VERSION ""

NS_ :

BS_:

BU_:

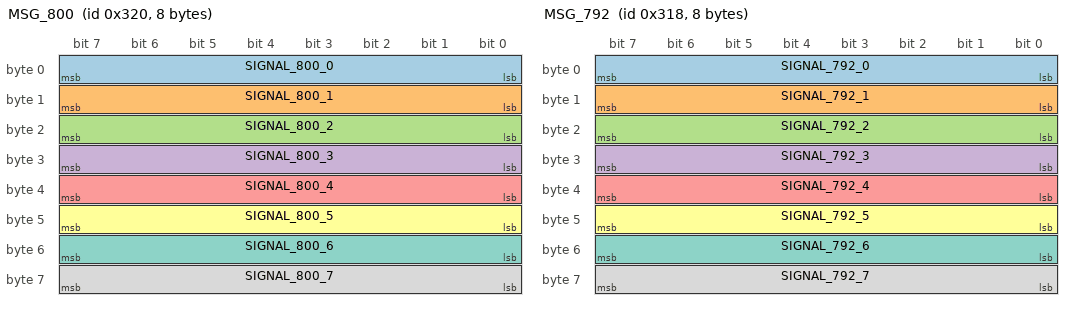
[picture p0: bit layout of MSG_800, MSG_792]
BO_ 800 MSG_800 : 8 VECTOR
    SG_ SIGNAL_800_0 : 0|8@1+ (1,0) [0|255] "" VECTOR
    SG_ SIGNAL_800_1 : 8|8@1+ (1,0) [0|255] "" VECTOR
    SG_ SIGNAL_800_2 : 16|8@1+ (1,0) [0|255] "" VECTOR
    SG_ SIGNAL_800_3 : 24|8@1+ (1,0) [0|255] "" VECTOR
    SG_ SIGNAL_800_4 : 32|8@1+ (1,0) [0|255] "" VECTOR
    SG_ SIGNAL_800_5 : 40|8@1+ (1,0) [0|255] "" VECTOR
    SG_ SIGNAL_800_6 : 48|8@1+ (1,0) [0|255] "" VECTOR
    SG_ SIGNAL_800_7 : 56|8@1+ (1,0) [0|255] "" VECTOR

BO_ 792 MSG_792 : 8 VECTOR
    SG_ SIGNAL_792_0 : 0|8@1+ (1,0) [0|255] "" VECTOR
    SG_ SIGNAL_792_1 : 8|8@1+ (1,0) [0|255] "" VECTOR
    SG_ SIGNAL_792_2 : 16|8@1+ (1,0) [0|255] "" VECTOR
    SG_ SIGNAL_792_3 : 24|8@1+ (1,0) [0|255] "" VECTOR
    SG_ SIGNAL_792_4 : 32|8@1+ (1,0) [0|255] "" VECTOR
    SG_ SIGNAL_792_5 : 40|8@1+ (1,0) [0|255] "" VECTOR
    SG_ SIGNAL_792_6 : 48|8@1+ (1,0) [0|255] "" VECTOR
    SG_ SIGNAL_792_7 : 56|8@1+ (1,0) [0|255] "" VECTOR

BO_ 287 MSG_287 : 5 VECTOR
    SG_ SIGNAL_287_0 : 0|8@1+ (1,0) [0|255] "" VECTOR
    SG_ SIGNAL_287_1 : 8|8@1+ (1,0) [0|255] "" VECTOR
    SG_ SIGNAL_287_2 : 16|8@1+ (1,0) [0|255] "" VECTOR
    SG_ SIGNAL_287_3 : 24|8@1+ (1,0) [0|255] "" VECTOR
    SG_ SIGNAL_287_4 : 32|8@1+ (1,0) [0|255] "" VECTOR

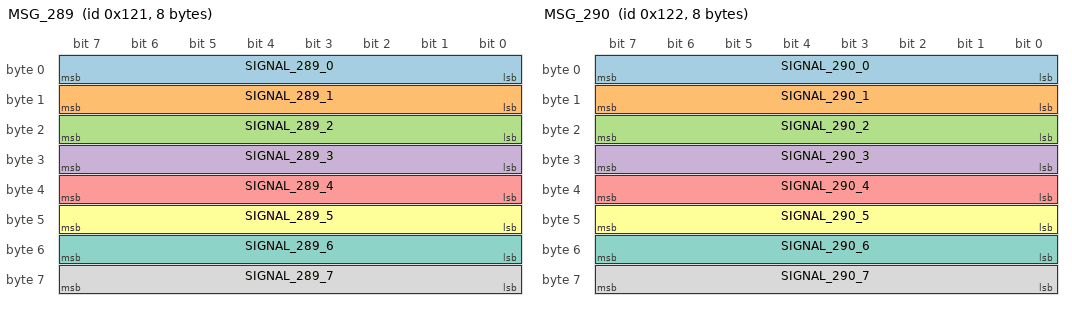
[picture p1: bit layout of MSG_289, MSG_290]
BO_ 289 MSG_289 : 8 VECTOR
    SG_ SIGNAL_289_0 : 0|8@1+ (1,0) [0|255] "" VECTOR
    SG_ SIGNAL_289_1 : 8|8@1+ (1,0) [0|255] "" VECTOR
    SG_ SIGNAL_289_2 : 16|8@1+ (1,0) [0|255] "" VECTOR
    SG_ SIGNAL_289_3 : 24|8@1+ (1,0) [0|255] "" VECTOR
    SG_ SIGNAL_289_4 : 32|8@1+ (1,0) [0|255] "" VECTOR
    SG_ SIGNAL_289_5 : 40|8@1+ (1,0) [0|255] "" VECTOR
    SG_ SIGNAL_289_6 : 48|8@1+ (1,0) [0|255] "" VECTOR
    SG_ SIGNAL_289_7 : 56|8@1+ (1,0) [0|255] "" VECTOR

BO_ 290 MSG_290 : 8 VECTOR
    SG_ SIGNAL_290_0 : 0|8@1+ (1,0) [0|255] "" VECTOR
    SG_ SIGNAL_290_1 : 8|8@1+ (1,0) [0|255] "" VECTOR
    SG_ SIGNAL_290_2 : 16|8@1+ (1,0) [0|255] "" VECTOR
    SG_ SIGNAL_290_3 : 24|8@1+ (1,0) [0|255] "" VECTOR
    SG_ SIGNAL_290_4 : 32|8@1+ (1,0) [0|255] "" VECTOR
    SG_ SIGNAL_290_5 : 40|8@1+ (1,0) [0|255] "" VECTOR
    SG_ SIGNAL_290_6 : 48|8@1+ (1,0) [0|255] "" VECTOR
    SG_ SIGNAL_290_7 : 56|8@1+ (1,0) [0|255] "" VECTOR

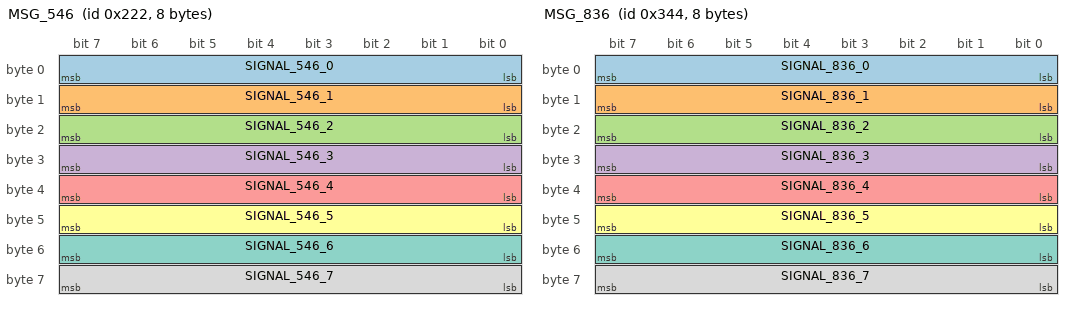
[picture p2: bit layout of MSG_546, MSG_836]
BO_ 546 MSG_546 : 8 VECTOR
    SG_ SIGNAL_546_0 : 0|8@1+ (1,0) [0|255] "" VECTOR
    SG_ SIGNAL_546_1 : 8|8@1+ (1,0) [0|255] "" VECTOR
    SG_ SIGNAL_546_2 : 16|8@1+ (1,0) [0|255] "" VECTOR
    SG_ SIGNAL_546_3 : 24|8@1+ (1,0) [0|255] "" VECTOR
    SG_ SIGNAL_546_4 : 32|8@1+ (1,0) [0|255] "" VECTOR
    SG_ SIGNAL_546_5 : 40|8@1+ (1,0) [0|255] "" VECTOR
    SG_ SIGNAL_546_6 : 48|8@1+ (1,0) [0|255] "" VECTOR
    SG_ SIGNAL_546_7 : 56|8@1+ (1,0) [0|255] "" VECTOR

BO_ 836 MSG_836 : 8 VECTOR
    SG_ SIGNAL_836_0 : 0|8@1+ (1,0) [0|255] "" VECTOR
    SG_ SIGNAL_836_1 : 8|8@1+ (1,0) [0|255] "" VECTOR
    SG_ SIGNAL_836_2 : 16|8@1+ (1,0) [0|255] "" VECTOR
    SG_ SIGNAL_836_3 : 24|8@1+ (1,0) [0|255] "" VECTOR
    SG_ SIGNAL_836_4 : 32|8@1+ (1,0) [0|255] "" VECTOR
    SG_ SIGNAL_836_5 : 40|8@1+ (1,0) [0|255] "" VECTOR
    SG_ SIGNAL_836_6 : 48|8@1+ (1,0) [0|255] "" VECTOR
    SG_ SIGNAL_836_7 : 56|8@1+ (1,0) [0|255] "" VECTOR

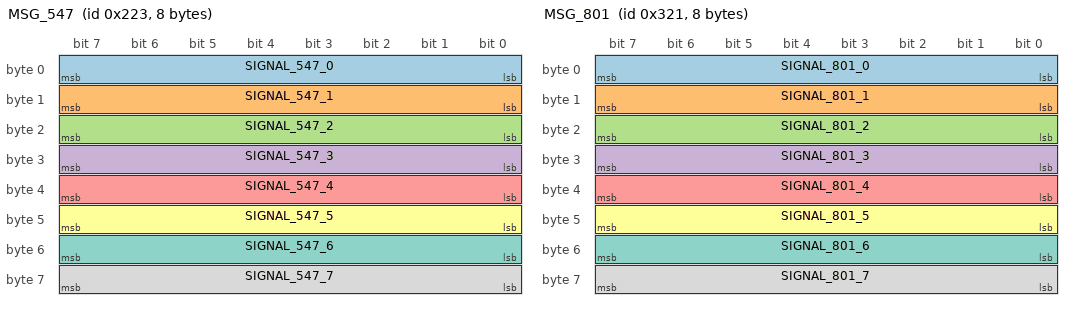
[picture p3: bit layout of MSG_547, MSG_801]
BO_ 547 MSG_547 : 8 VECTOR
    SG_ SIGNAL_547_0 : 0|8@1+ (1,0) [0|255] "" VECTOR
    SG_ SIGNAL_547_1 : 8|8@1+ (1,0) [0|255] "" VECTOR
    SG_ SIGNAL_547_2 : 16|8@1+ (1,0) [0|255] "" VECTOR
    SG_ SIGNAL_547_3 : 24|8@1+ (1,0) [0|255] "" VECTOR
    SG_ SIGNAL_547_4 : 32|8@1+ (1,0) [0|255] "" VECTOR
    SG_ SIGNAL_547_5 : 40|8@1+ (1,0) [0|255] "" VECTOR
    SG_ SIGNAL_547_6 : 48|8@1+ (1,0) [0|255] "" VECTOR
    SG_ SIGNAL_547_7 : 56|8@1+ (1,0) [0|255] "" VECTOR

BO_ 801 MSG_801 : 8 VECTOR
    SG_ SIGNAL_801_0 : 0|8@1+ (1,0) [0|255] "" VECTOR
    SG_ SIGNAL_801_1 : 8|8@1+ (1,0) [0|255] "" VECTOR
    SG_ SIGNAL_801_2 : 16|8@1+ (1,0) [0|255] "" VECTOR
    SG_ SIGNAL_801_3 : 24|8@1+ (1,0) [0|255] "" VECTOR
    SG_ SIGNAL_801_4 : 32|8@1+ (1,0) [0|255] "" VECTOR
    SG_ SIGNAL_801_5 : 40|8@1+ (1,0) [0|255] "" VECTOR
    SG_ SIGNAL_801_6 : 48|8@1+ (1,0) [0|255] "" VECTOR
    SG_ SIGNAL_801_7 : 56|8@1+ (1,0) [0|255] "" VECTOR

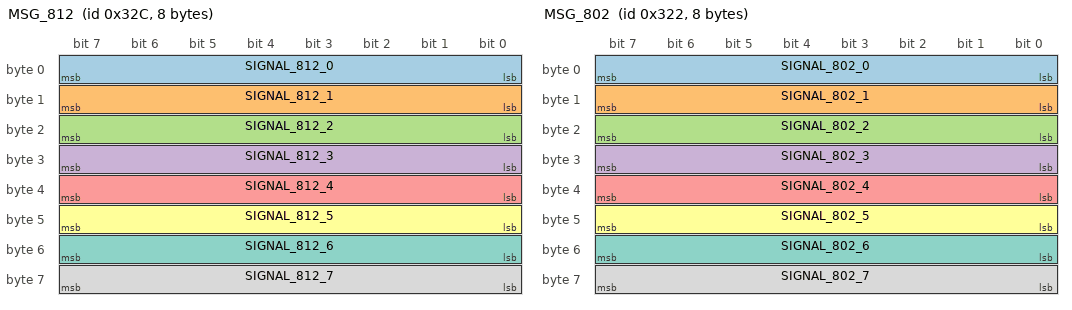
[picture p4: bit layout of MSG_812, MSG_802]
BO_ 812 MSG_812 : 8 VECTOR
    SG_ SIGNAL_812_0 : 0|8@1+ (1,0) [0|255] "" VECTOR
    SG_ SIGNAL_812_1 : 8|8@1+ (1,0) [0|255] "" VECTOR
    SG_ SIGNAL_812_2 : 16|8@1+ (1,0) [0|255] "" VECTOR
    SG_ SIGNAL_812_3 : 24|8@1+ (1,0) [0|255] "" VECTOR
    SG_ SIGNAL_812_4 : 32|8@1+ (1,0) [0|255] "" VECTOR
    SG_ SIGNAL_812_5 : 40|8@1+ (1,0) [0|255] "" VECTOR
    SG_ SIGNAL_812_6 : 48|8@1+ (1,0) [0|255] "" VECTOR
    SG_ SIGNAL_812_7 : 56|8@1+ (1,0) [0|255] "" VECTOR

BO_ 802 MSG_802 : 8 VECTOR
    SG_ SIGNAL_802_0 : 0|8@1+ (1,0) [0|255] "" VECTOR
    SG_ SIGNAL_802_1 : 8|8@1+ (1,0) [0|255] "" VECTOR
    SG_ SIGNAL_802_2 : 16|8@1+ (1,0) [0|255] "" VECTOR
    SG_ SIGNAL_802_3 : 24|8@1+ (1,0) [0|255] "" VECTOR
    SG_ SIGNAL_802_4 : 32|8@1+ (1,0) [0|255] "" VECTOR
    SG_ SIGNAL_802_5 : 40|8@1+ (1,0) [0|255] "" VECTOR
    SG_ SIGNAL_802_6 : 48|8@1+ (1,0) [0|255] "" VECTOR
    SG_ SIGNAL_802_7 : 56|8@1+ (1,0) [0|255] "" VECTOR

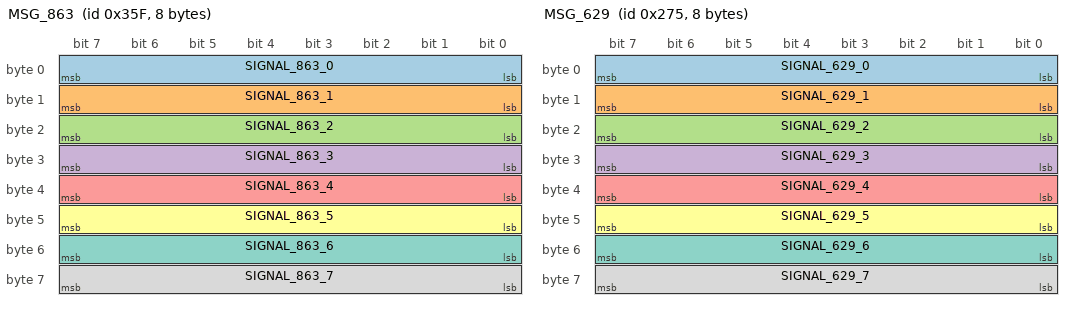
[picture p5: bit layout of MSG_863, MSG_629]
BO_ 863 MSG_863 : 8 VECTOR
    SG_ SIGNAL_863_0 : 0|8@1+ (1,0) [0|255] "" VECTOR
    SG_ SIGNAL_863_1 : 8|8@1+ (1,0) [0|255] "" VECTOR
    SG_ SIGNAL_863_2 : 16|8@1+ (1,0) [0|255] "" VECTOR
    SG_ SIGNAL_863_3 : 24|8@1+ (1,0) [0|255] "" VECTOR
    SG_ SIGNAL_863_4 : 32|8@1+ (1,0) [0|255] "" VECTOR
    SG_ SIGNAL_863_5 : 40|8@1+ (1,0) [0|255] "" VECTOR
    SG_ SIGNAL_863_6 : 48|8@1+ (1,0) [0|255] "" VECTOR
    SG_ SIGNAL_863_7 : 56|8@1+ (1,0) [0|255] "" VECTOR

BO_ 629 MSG_629 : 8 VECTOR
    SG_ SIGNAL_629_0 : 0|8@1+ (1,0) [0|255] "" VECTOR
    SG_ SIGNAL_629_1 : 8|8@1+ (1,0) [0|255] "" VECTOR
    SG_ SIGNAL_629_2 : 16|8@1+ (1,0) [0|255] "" VECTOR
    SG_ SIGNAL_629_3 : 24|8@1+ (1,0) [0|255] "" VECTOR
    SG_ SIGNAL_629_4 : 32|8@1+ (1,0) [0|255] "" VECTOR
    SG_ SIGNAL_629_5 : 40|8@1+ (1,0) [0|255] "" VECTOR
    SG_ SIGNAL_629_6 : 48|8@1+ (1,0) [0|255] "" VECTOR
    SG_ SIGNAL_629_7 : 56|8@1+ (1,0) [0|255] "" VECTOR

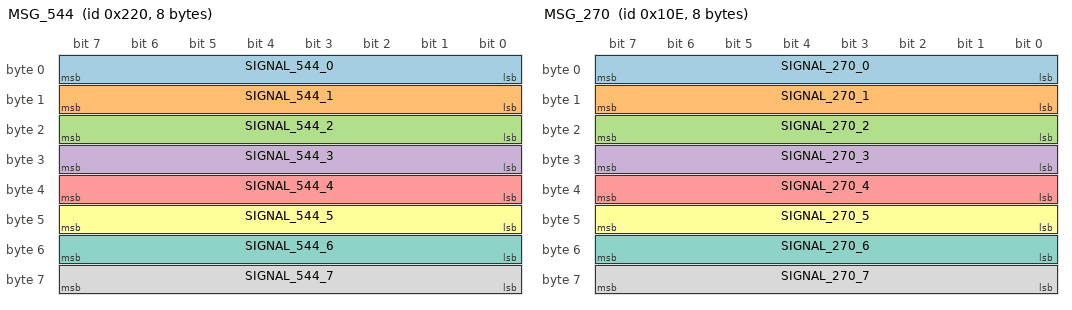
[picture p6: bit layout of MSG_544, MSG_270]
BO_ 544 MSG_544 : 8 VECTOR
    SG_ SIGNAL_544_0 : 0|8@1+ (1,0) [0|255] "" VECTOR
    SG_ SIGNAL_544_1 : 8|8@1+ (1,0) [0|255] "" VECTOR
    SG_ SIGNAL_544_2 : 16|8@1+ (1,0) [0|255] "" VECTOR
    SG_ SIGNAL_544_3 : 24|8@1+ (1,0) [0|255] "" VECTOR
    SG_ SIGNAL_544_4 : 32|8@1+ (1,0) [0|255] "" VECTOR
    SG_ SIGNAL_544_5 : 40|8@1+ (1,0) [0|255] "" VECTOR
    SG_ SIGNAL_544_6 : 48|8@1+ (1,0) [0|255] "" VECTOR
    SG_ SIGNAL_544_7 : 56|8@1+ (1,0) [0|255] "" VECTOR

BO_ 270 MSG_270 : 8 VECTOR
    SG_ SIGNAL_270_0 : 0|8@1+ (1,0) [0|255] "" VECTOR
    SG_ SIGNAL_270_1 : 8|8@1+ (1,0) [0|255] "" VECTOR
    SG_ SIGNAL_270_2 : 16|8@1+ (1,0) [0|255] "" VECTOR
    SG_ SIGNAL_270_3 : 24|8@1+ (1,0) [0|255] "" VECTOR
    SG_ SIGNAL_270_4 : 32|8@1+ (1,0) [0|255] "" VECTOR
    SG_ SIGNAL_270_5 : 40|8@1+ (1,0) [0|255] "" VECTOR
    SG_ SIGNAL_270_6 : 48|8@1+ (1,0) [0|255] "" VECTOR
    SG_ SIGNAL_270_7 : 56|8@1+ (1,0) [0|255] "" VECTOR

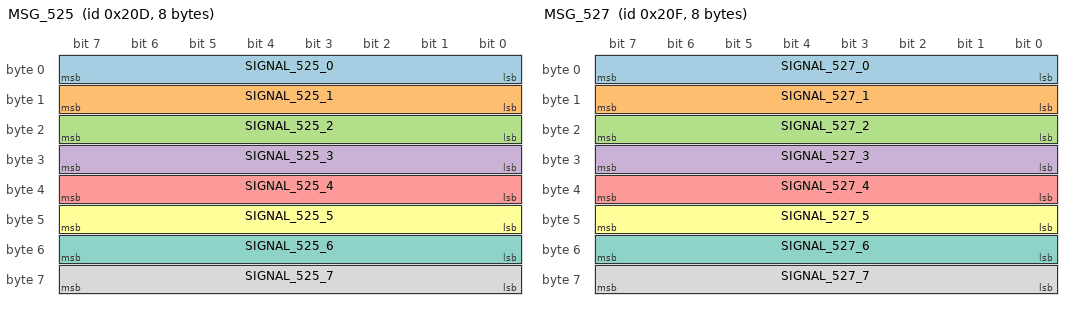
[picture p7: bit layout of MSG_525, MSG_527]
BO_ 525 MSG_525 : 8 VECTOR
    SG_ SIGNAL_525_0 : 0|8@1+ (1,0) [0|255] "" VECTOR
    SG_ SIGNAL_525_1 : 8|8@1+ (1,0) [0|255] "" VECTOR
    SG_ SIGNAL_525_2 : 16|8@1+ (1,0) [0|255] "" VECTOR
    SG_ SIGNAL_525_3 : 24|8@1+ (1,0) [0|255] "" VECTOR
    SG_ SIGNAL_525_4 : 32|8@1+ (1,0) [0|255] "" VECTOR
    SG_ SIGNAL_525_5 : 40|8@1+ (1,0) [0|255] "" VECTOR
    SG_ SIGNAL_525_6 : 48|8@1+ (1,0) [0|255] "" VECTOR
    SG_ SIGNAL_525_7 : 56|8@1+ (1,0) [0|255] "" VECTOR

BO_ 527 MSG_527 : 8 VECTOR
    SG_ SIGNAL_527_0 : 0|8@1+ (1,0) [0|255] "" VECTOR
    SG_ SIGNAL_527_1 : 8|8@1+ (1,0) [0|255] "" VECTOR
    SG_ SIGNAL_527_2 : 16|8@1+ (1,0) [0|255] "" VECTOR
    SG_ SIGNAL_527_3 : 24|8@1+ (1,0) [0|255] "" VECTOR
    SG_ SIGNAL_527_4 : 32|8@1+ (1,0) [0|255] "" VECTOR
    SG_ SIGNAL_527_5 : 40|8@1+ (1,0) [0|255] "" VECTOR
    SG_ SIGNAL_527_6 : 48|8@1+ (1,0) [0|255] "" VECTOR
    SG_ SIGNAL_527_7 : 56|8@1+ (1,0) [0|255] "" VECTOR

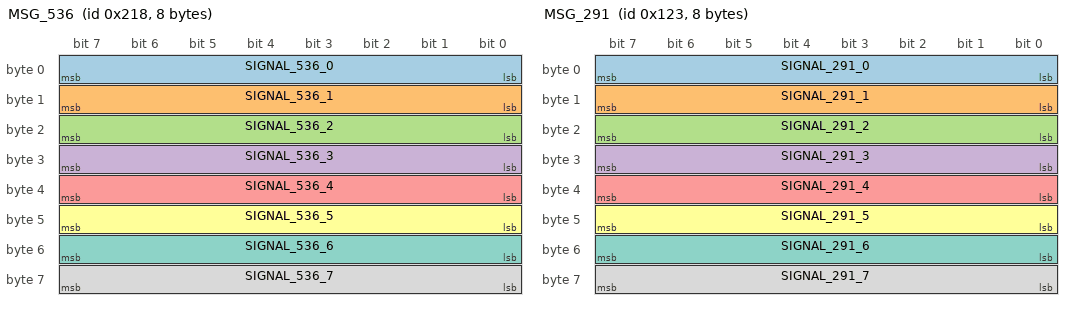
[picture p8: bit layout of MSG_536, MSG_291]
BO_ 536 MSG_536 : 8 VECTOR
    SG_ SIGNAL_536_0 : 0|8@1+ (1,0) [0|255] "" VECTOR
    SG_ SIGNAL_536_1 : 8|8@1+ (1,0) [0|255] "" VECTOR
    SG_ SIGNAL_536_2 : 16|8@1+ (1,0) [0|255] "" VECTOR
    SG_ SIGNAL_536_3 : 24|8@1+ (1,0) [0|255] "" VECTOR
    SG_ SIGNAL_536_4 : 32|8@1+ (1,0) [0|255] "" VECTOR
    SG_ SIGNAL_536_5 : 40|8@1+ (1,0) [0|255] "" VECTOR
    SG_ SIGNAL_536_6 : 48|8@1+ (1,0) [0|255] "" VECTOR
    SG_ SIGNAL_536_7 : 56|8@1+ (1,0) [0|255] "" VECTOR

BO_ 291 MSG_291 : 8 VECTOR
    SG_ SIGNAL_291_0 : 0|8@1+ (1,0) [0|255] "" VECTOR
    SG_ SIGNAL_291_1 : 8|8@1+ (1,0) [0|255] "" VECTOR
    SG_ SIGNAL_291_2 : 16|8@1+ (1,0) [0|255] "" VECTOR
    SG_ SIGNAL_291_3 : 24|8@1+ (1,0) [0|255] "" VECTOR
    SG_ SIGNAL_291_4 : 32|8@1+ (1,0) [0|255] "" VECTOR
    SG_ SIGNAL_291_5 : 40|8@1+ (1,0) [0|255] "" VECTOR
    SG_ SIGNAL_291_6 : 48|8@1+ (1,0) [0|255] "" VECTOR
    SG_ SIGNAL_291_7 : 56|8@1+ (1,0) [0|255] "" VECTOR

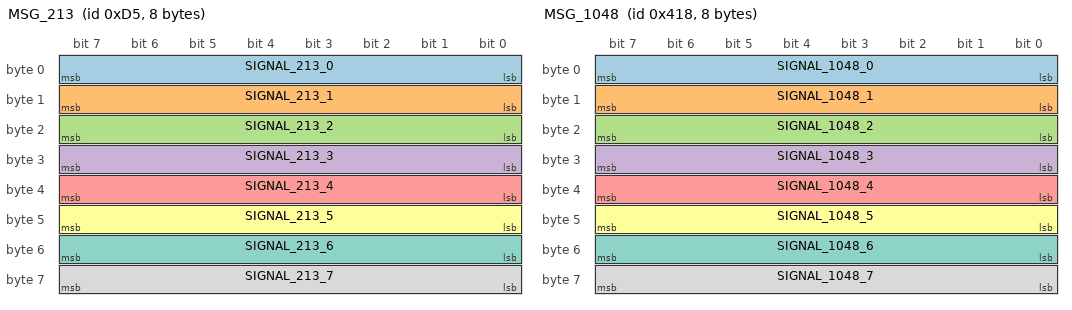
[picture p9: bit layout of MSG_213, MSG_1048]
BO_ 213 MSG_213 : 8 VECTOR
    SG_ SIGNAL_213_0 : 0|8@1+ (1,0) [0|255] "" VECTOR
    SG_ SIGNAL_213_1 : 8|8@1+ (1,0) [0|255] "" VECTOR
    SG_ SIGNAL_213_2 : 16|8@1+ (1,0) [0|255] "" VECTOR
    SG_ SIGNAL_213_3 : 24|8@1+ (1,0) [0|255] "" VECTOR
    SG_ SIGNAL_213_4 : 32|8@1+ (1,0) [0|255] "" VECTOR
    SG_ SIGNAL_213_5 : 40|8@1+ (1,0) [0|255] "" VECTOR
    SG_ SIGNAL_213_6 : 48|8@1+ (1,0) [0|255] "" VECTOR
    SG_ SIGNAL_213_7 : 56|8@1+ (1,0) [0|255] "" VECTOR

BO_ 1048 MSG_1048 : 8 VECTOR
    SG_ SIGNAL_1048_0 : 0|8@1+ (1,0) [0|255] "" VECTOR
    SG_ SIGNAL_1048_1 : 8|8@1+ (1,0) [0|255] "" VECTOR
    SG_ SIGNAL_1048_2 : 16|8@1+ (1,0) [0|255] "" VECTOR
    SG_ SIGNAL_1048_3 : 24|8@1+ (1,0) [0|255] "" VECTOR
    SG_ SIGNAL_1048_4 : 32|8@1+ (1,0) [0|255] "" VECTOR
    SG_ SIGNAL_1048_5 : 40|8@1+ (1,0) [0|255] "" VECTOR
    SG_ SIGNAL_1048_6 : 48|8@1+ (1,0) [0|255] "" VECTOR
    SG_ SIGNAL_1048_7 : 56|8@1+ (1,0) [0|255] "" VECTOR

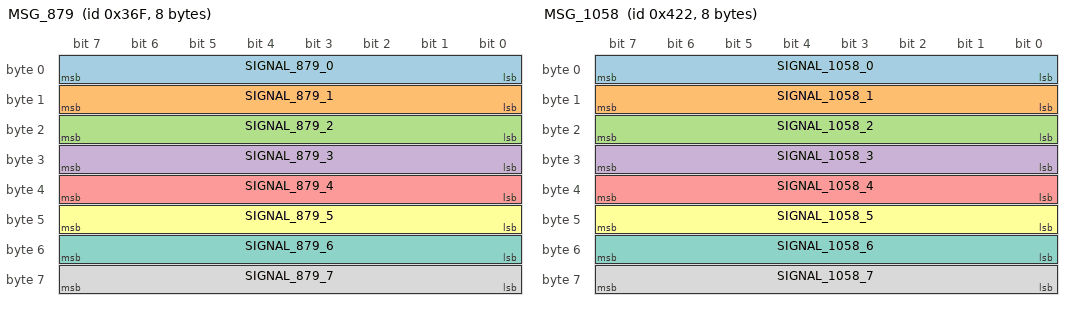
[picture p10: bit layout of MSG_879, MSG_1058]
BO_ 879 MSG_879 : 8 VECTOR
    SG_ SIGNAL_879_0 : 0|8@1+ (1,0) [0|255] "" VECTOR
    SG_ SIGNAL_879_1 : 8|8@1+ (1,0) [0|255] "" VECTOR
    SG_ SIGNAL_879_2 : 16|8@1+ (1,0) [0|255] "" VECTOR
    SG_ SIGNAL_879_3 : 24|8@1+ (1,0) [0|255] "" VECTOR
    SG_ SIGNAL_879_4 : 32|8@1+ (1,0) [0|255] "" VECTOR
    SG_ SIGNAL_879_5 : 40|8@1+ (1,0) [0|255] "" VECTOR
    SG_ SIGNAL_879_6 : 48|8@1+ (1,0) [0|255] "" VECTOR
    SG_ SIGNAL_879_7 : 56|8@1+ (1,0) [0|255] "" VECTOR

BO_ 1058 MSG_1058 : 8 VECTOR
    SG_ SIGNAL_1058_0 : 0|8@1+ (1,0) [0|255] "" VECTOR
    SG_ SIGNAL_1058_1 : 8|8@1+ (1,0) [0|255] "" VECTOR
    SG_ SIGNAL_1058_2 : 16|8@1+ (1,0) [0|255] "" VECTOR
    SG_ SIGNAL_1058_3 : 24|8@1+ (1,0) [0|255] "" VECTOR
    SG_ SIGNAL_1058_4 : 32|8@1+ (1,0) [0|255] "" VECTOR
    SG_ SIGNAL_1058_5 : 40|8@1+ (1,0) [0|255] "" VECTOR
    SG_ SIGNAL_1058_6 : 48|8@1+ (1,0) [0|255] "" VECTOR
    SG_ SIGNAL_1058_7 : 56|8@1+ (1,0) [0|255] "" VECTOR

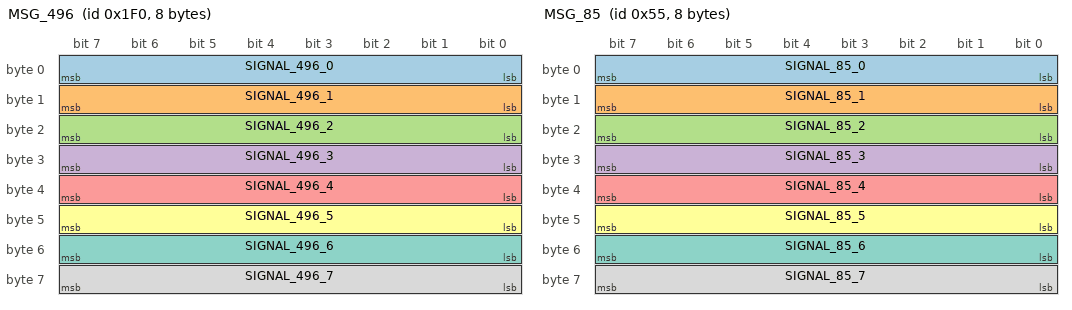
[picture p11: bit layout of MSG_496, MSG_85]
BO_ 496 MSG_496 : 8 VECTOR
    SG_ SIGNAL_496_0 : 0|8@1+ (1,0) [0|255] "" VECTOR
    SG_ SIGNAL_496_1 : 8|8@1+ (1,0) [0|255] "" VECTOR
    SG_ SIGNAL_496_2 : 16|8@1+ (1,0) [0|255] "" VECTOR
    SG_ SIGNAL_496_3 : 24|8@1+ (1,0) [0|255] "" VECTOR
    SG_ SIGNAL_496_4 : 32|8@1+ (1,0) [0|255] "" VECTOR
    SG_ SIGNAL_496_5 : 40|8@1+ (1,0) [0|255] "" VECTOR
    SG_ SIGNAL_496_6 : 48|8@1+ (1,0) [0|255] "" VECTOR
    SG_ SIGNAL_496_7 : 56|8@1+ (1,0) [0|255] "" VECTOR

BO_ 85 MSG_85 : 8 VECTOR
    SG_ SIGNAL_85_0 : 0|8@1+ (1,0) [0|255] "" VECTOR
    SG_ SIGNAL_85_1 : 8|8@1+ (1,0) [0|255] "" VECTOR
    SG_ SIGNAL_85_2 : 16|8@1+ (1,0) [0|255] "" VECTOR
    SG_ SIGNAL_85_3 : 24|8@1+ (1,0) [0|255] "" VECTOR
    SG_ SIGNAL_85_4 : 32|8@1+ (1,0) [0|255] "" VECTOR
    SG_ SIGNAL_85_5 : 40|8@1+ (1,0) [0|255] "" VECTOR
    SG_ SIGNAL_85_6 : 48|8@1+ (1,0) [0|255] "" VECTOR
    SG_ SIGNAL_85_7 : 56|8@1+ (1,0) [0|255] "" VECTOR

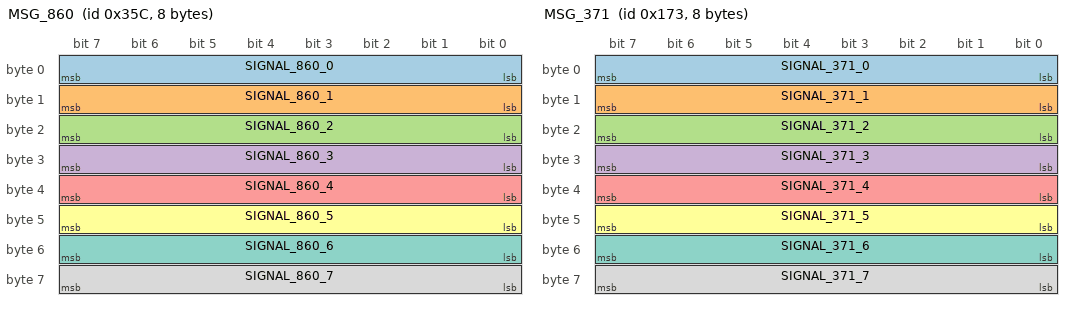
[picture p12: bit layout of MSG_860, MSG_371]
BO_ 860 MSG_860 : 8 VECTOR
    SG_ SIGNAL_860_0 : 0|8@1+ (1,0) [0|255] "" VECTOR
    SG_ SIGNAL_860_1 : 8|8@1+ (1,0) [0|255] "" VECTOR
    SG_ SIGNAL_860_2 : 16|8@1+ (1,0) [0|255] "" VECTOR
    SG_ SIGNAL_860_3 : 24|8@1+ (1,0) [0|255] "" VECTOR
    SG_ SIGNAL_860_4 : 32|8@1+ (1,0) [0|255] "" VECTOR
    SG_ SIGNAL_860_5 : 40|8@1+ (1,0) [0|255] "" VECTOR
    SG_ SIGNAL_860_6 : 48|8@1+ (1,0) [0|255] "" VECTOR
    SG_ SIGNAL_860_7 : 56|8@1+ (1,0) [0|255] "" VECTOR

BO_ 371 MSG_371 : 8 VECTOR
    SG_ SIGNAL_371_0 : 0|8@1+ (1,0) [0|255] "" VECTOR
    SG_ SIGNAL_371_1 : 8|8@1+ (1,0) [0|255] "" VECTOR
    SG_ SIGNAL_371_2 : 16|8@1+ (1,0) [0|255] "" VECTOR
    SG_ SIGNAL_371_3 : 24|8@1+ (1,0) [0|255] "" VECTOR
    SG_ SIGNAL_371_4 : 32|8@1+ (1,0) [0|255] "" VECTOR
    SG_ SIGNAL_371_5 : 40|8@1+ (1,0) [0|255] "" VECTOR
    SG_ SIGNAL_371_6 : 48|8@1+ (1,0) [0|255] "" VECTOR
    SG_ SIGNAL_371_7 : 56|8@1+ (1,0) [0|255] "" VECTOR

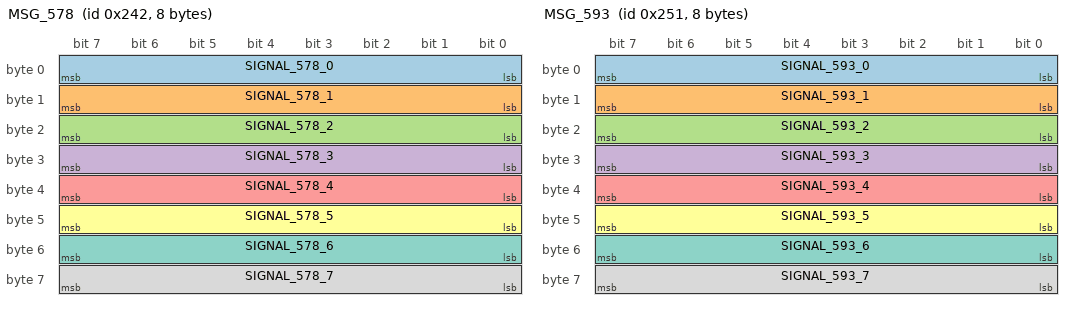
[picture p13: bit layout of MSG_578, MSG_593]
BO_ 578 MSG_578 : 8 VECTOR
    SG_ SIGNAL_578_0 : 0|8@1+ (1,0) [0|255] "" VECTOR
    SG_ SIGNAL_578_1 : 8|8@1+ (1,0) [0|255] "" VECTOR
    SG_ SIGNAL_578_2 : 16|8@1+ (1,0) [0|255] "" VECTOR
    SG_ SIGNAL_578_3 : 24|8@1+ (1,0) [0|255] "" VECTOR
    SG_ SIGNAL_578_4 : 32|8@1+ (1,0) [0|255] "" VECTOR
    SG_ SIGNAL_578_5 : 40|8@1+ (1,0) [0|255] "" VECTOR
    SG_ SIGNAL_578_6 : 48|8@1+ (1,0) [0|255] "" VECTOR
    SG_ SIGNAL_578_7 : 56|8@1+ (1,0) [0|255] "" VECTOR

BO_ 593 MSG_593 : 8 VECTOR
    SG_ SIGNAL_593_0 : 0|8@1+ (1,0) [0|255] "" VECTOR
    SG_ SIGNAL_593_1 : 8|8@1+ (1,0) [0|255] "" VECTOR
    SG_ SIGNAL_593_2 : 16|8@1+ (1,0) [0|255] "" VECTOR
    SG_ SIGNAL_593_3 : 24|8@1+ (1,0) [0|255] "" VECTOR
    SG_ SIGNAL_593_4 : 32|8@1+ (1,0) [0|255] "" VECTOR
    SG_ SIGNAL_593_5 : 40|8@1+ (1,0) [0|255] "" VECTOR
    SG_ SIGNAL_593_6 : 48|8@1+ (1,0) [0|255] "" VECTOR
    SG_ SIGNAL_593_7 : 56|8@1+ (1,0) [0|255] "" VECTOR

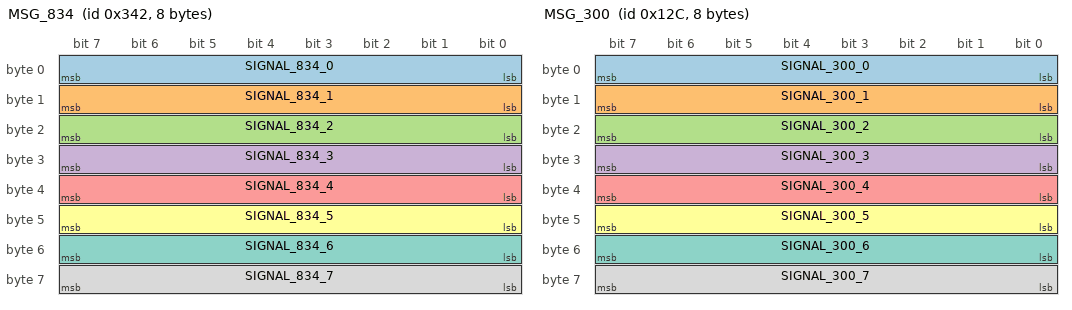
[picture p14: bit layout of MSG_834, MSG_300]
BO_ 834 MSG_834 : 8 VECTOR
    SG_ SIGNAL_834_0 : 0|8@1+ (1,0) [0|255] "" VECTOR
    SG_ SIGNAL_834_1 : 8|8@1+ (1,0) [0|255] "" VECTOR
    SG_ SIGNAL_834_2 : 16|8@1+ (1,0) [0|255] "" VECTOR
    SG_ SIGNAL_834_3 : 24|8@1+ (1,0) [0|255] "" VECTOR
    SG_ SIGNAL_834_4 : 32|8@1+ (1,0) [0|255] "" VECTOR
    SG_ SIGNAL_834_5 : 40|8@1+ (1,0) [0|255] "" VECTOR
    SG_ SIGNAL_834_6 : 48|8@1+ (1,0) [0|255] "" VECTOR
    SG_ SIGNAL_834_7 : 56|8@1+ (1,0) [0|255] "" VECTOR

BO_ 300 MSG_300 : 8 VECTOR
    SG_ SIGNAL_300_0 : 0|8@1+ (1,0) [0|255] "" VECTOR
    SG_ SIGNAL_300_1 : 8|8@1+ (1,0) [0|255] "" VECTOR
    SG_ SIGNAL_300_2 : 16|8@1+ (1,0) [0|255] "" VECTOR
    SG_ SIGNAL_300_3 : 24|8@1+ (1,0) [0|255] "" VECTOR
    SG_ SIGNAL_300_4 : 32|8@1+ (1,0) [0|255] "" VECTOR
    SG_ SIGNAL_300_5 : 40|8@1+ (1,0) [0|255] "" VECTOR
    SG_ SIGNAL_300_6 : 48|8@1+ (1,0) [0|255] "" VECTOR
    SG_ SIGNAL_300_7 : 56|8@1+ (1,0) [0|255] "" VECTOR

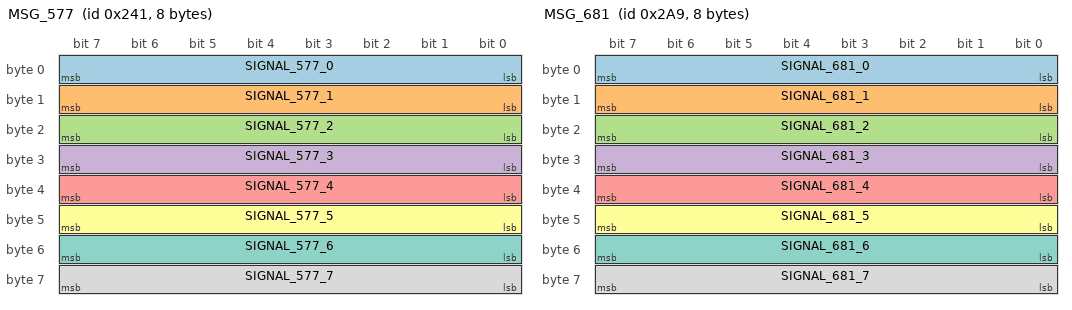
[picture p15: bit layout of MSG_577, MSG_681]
BO_ 577 MSG_577 : 8 VECTOR
    SG_ SIGNAL_577_0 : 0|8@1+ (1,0) [0|255] "" VECTOR
    SG_ SIGNAL_577_1 : 8|8@1+ (1,0) [0|255] "" VECTOR
    SG_ SIGNAL_577_2 : 16|8@1+ (1,0) [0|255] "" VECTOR
    SG_ SIGNAL_577_3 : 24|8@1+ (1,0) [0|255] "" VECTOR
    SG_ SIGNAL_577_4 : 32|8@1+ (1,0) [0|255] "" VECTOR
    SG_ SIGNAL_577_5 : 40|8@1+ (1,0) [0|255] "" VECTOR
    SG_ SIGNAL_577_6 : 48|8@1+ (1,0) [0|255] "" VECTOR
    SG_ SIGNAL_577_7 : 56|8@1+ (1,0) [0|255] "" VECTOR

BO_ 681 MSG_681 : 8 VECTOR
    SG_ SIGNAL_681_0 : 0|8@1+ (1,0) [0|255] "" VECTOR
    SG_ SIGNAL_681_1 : 8|8@1+ (1,0) [0|255] "" VECTOR
    SG_ SIGNAL_681_2 : 16|8@1+ (1,0) [0|255] "" VECTOR
    SG_ SIGNAL_681_3 : 24|8@1+ (1,0) [0|255] "" VECTOR
    SG_ SIGNAL_681_4 : 32|8@1+ (1,0) [0|255] "" VECTOR
    SG_ SIGNAL_681_5 : 40|8@1+ (1,0) [0|255] "" VECTOR
    SG_ SIGNAL_681_6 : 48|8@1+ (1,0) [0|255] "" VECTOR
    SG_ SIGNAL_681_7 : 56|8@1+ (1,0) [0|255] "" VECTOR

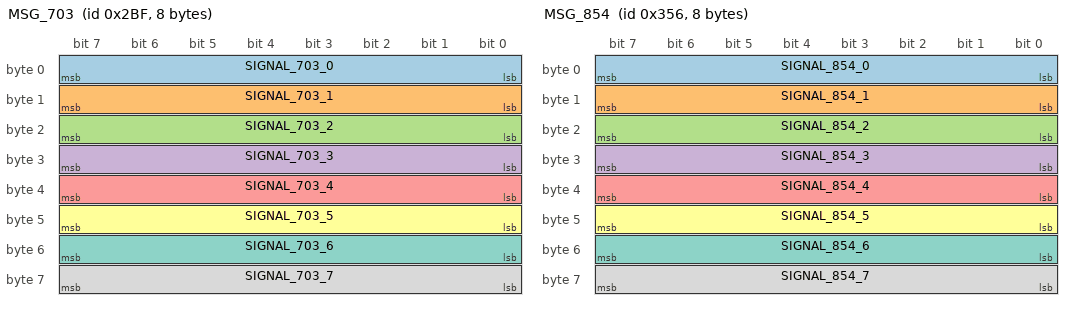
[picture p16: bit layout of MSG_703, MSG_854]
BO_ 703 MSG_703 : 8 VECTOR
    SG_ SIGNAL_703_0 : 0|8@1+ (1,0) [0|255] "" VECTOR
    SG_ SIGNAL_703_1 : 8|8@1+ (1,0) [0|255] "" VECTOR
    SG_ SIGNAL_703_2 : 16|8@1+ (1,0) [0|255] "" VECTOR
    SG_ SIGNAL_703_3 : 24|8@1+ (1,0) [0|255] "" VECTOR
    SG_ SIGNAL_703_4 : 32|8@1+ (1,0) [0|255] "" VECTOR
    SG_ SIGNAL_703_5 : 40|8@1+ (1,0) [0|255] "" VECTOR
    SG_ SIGNAL_703_6 : 48|8@1+ (1,0) [0|255] "" VECTOR
    SG_ SIGNAL_703_7 : 56|8@1+ (1,0) [0|255] "" VECTOR

BO_ 854 MSG_854 : 8 VECTOR
    SG_ SIGNAL_854_0 : 0|8@1+ (1,0) [0|255] "" VECTOR
    SG_ SIGNAL_854_1 : 8|8@1+ (1,0) [0|255] "" VECTOR
    SG_ SIGNAL_854_2 : 16|8@1+ (1,0) [0|255] "" VECTOR
    SG_ SIGNAL_854_3 : 24|8@1+ (1,0) [0|255] "" VECTOR
    SG_ SIGNAL_854_4 : 32|8@1+ (1,0) [0|255] "" VECTOR
    SG_ SIGNAL_854_5 : 40|8@1+ (1,0) [0|255] "" VECTOR
    SG_ SIGNAL_854_6 : 48|8@1+ (1,0) [0|255] "" VECTOR
    SG_ SIGNAL_854_7 : 56|8@1+ (1,0) [0|255] "" VECTOR

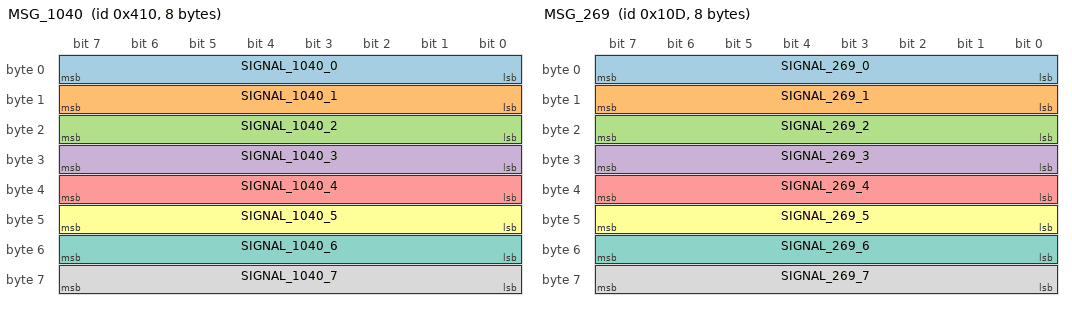
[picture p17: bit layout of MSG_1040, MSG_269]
BO_ 1040 MSG_1040 : 8 VECTOR
    SG_ SIGNAL_1040_0 : 0|8@1+ (1,0) [0|255] "" VECTOR
    SG_ SIGNAL_1040_1 : 8|8@1+ (1,0) [0|255] "" VECTOR
    SG_ SIGNAL_1040_2 : 16|8@1+ (1,0) [0|255] "" VECTOR
    SG_ SIGNAL_1040_3 : 24|8@1+ (1,0) [0|255] "" VECTOR
    SG_ SIGNAL_1040_4 : 32|8@1+ (1,0) [0|255] "" VECTOR
    SG_ SIGNAL_1040_5 : 40|8@1+ (1,0) [0|255] "" VECTOR
    SG_ SIGNAL_1040_6 : 48|8@1+ (1,0) [0|255] "" VECTOR
    SG_ SIGNAL_1040_7 : 56|8@1+ (1,0) [0|255] "" VECTOR

BO_ 269 MSG_269 : 8 VECTOR
    SG_ SIGNAL_269_0 : 0|8@1+ (1,0) [0|255] "" VECTOR
    SG_ SIGNAL_269_1 : 8|8@1+ (1,0) [0|255] "" VECTOR
    SG_ SIGNAL_269_2 : 16|8@1+ (1,0) [0|255] "" VECTOR
    SG_ SIGNAL_269_3 : 24|8@1+ (1,0) [0|255] "" VECTOR
    SG_ SIGNAL_269_4 : 32|8@1+ (1,0) [0|255] "" VECTOR
    SG_ SIGNAL_269_5 : 40|8@1+ (1,0) [0|255] "" VECTOR
    SG_ SIGNAL_269_6 : 48|8@1+ (1,0) [0|255] "" VECTOR
    SG_ SIGNAL_269_7 : 56|8@1+ (1,0) [0|255] "" VECTOR

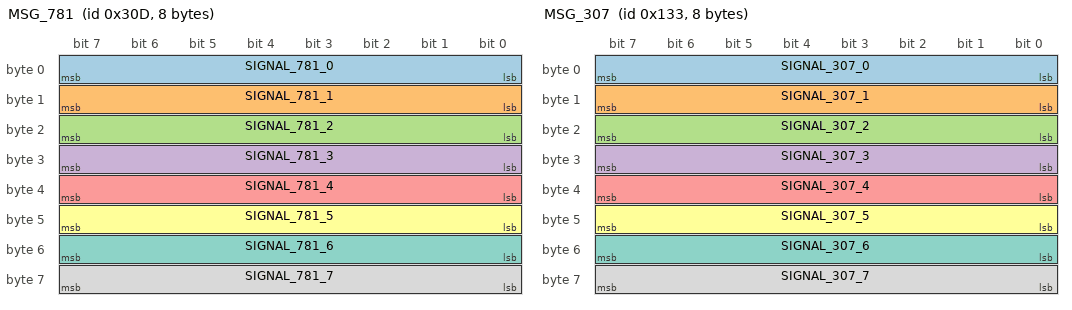
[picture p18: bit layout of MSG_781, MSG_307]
BO_ 781 MSG_781 : 8 VECTOR
    SG_ SIGNAL_781_0 : 0|8@1+ (1,0) [0|255] "" VECTOR
    SG_ SIGNAL_781_1 : 8|8@1+ (1,0) [0|255] "" VECTOR
    SG_ SIGNAL_781_2 : 16|8@1+ (1,0) [0|255] "" VECTOR
    SG_ SIGNAL_781_3 : 24|8@1+ (1,0) [0|255] "" VECTOR
    SG_ SIGNAL_781_4 : 32|8@1+ (1,0) [0|255] "" VECTOR
    SG_ SIGNAL_781_5 : 40|8@1+ (1,0) [0|255] "" VECTOR
    SG_ SIGNAL_781_6 : 48|8@1+ (1,0) [0|255] "" VECTOR
    SG_ SIGNAL_781_7 : 56|8@1+ (1,0) [0|255] "" VECTOR

BO_ 307 MSG_307 : 8 VECTOR
    SG_ SIGNAL_307_0 : 0|8@1+ (1,0) [0|255] "" VECTOR
    SG_ SIGNAL_307_1 : 8|8@1+ (1,0) [0|255] "" VECTOR
    SG_ SIGNAL_307_2 : 16|8@1+ (1,0) [0|255] "" VECTOR
    SG_ SIGNAL_307_3 : 24|8@1+ (1,0) [0|255] "" VECTOR
    SG_ SIGNAL_307_4 : 32|8@1+ (1,0) [0|255] "" VECTOR
    SG_ SIGNAL_307_5 : 40|8@1+ (1,0) [0|255] "" VECTOR
    SG_ SIGNAL_307_6 : 48|8@1+ (1,0) [0|255] "" VECTOR
    SG_ SIGNAL_307_7 : 56|8@1+ (1,0) [0|255] "" VECTOR

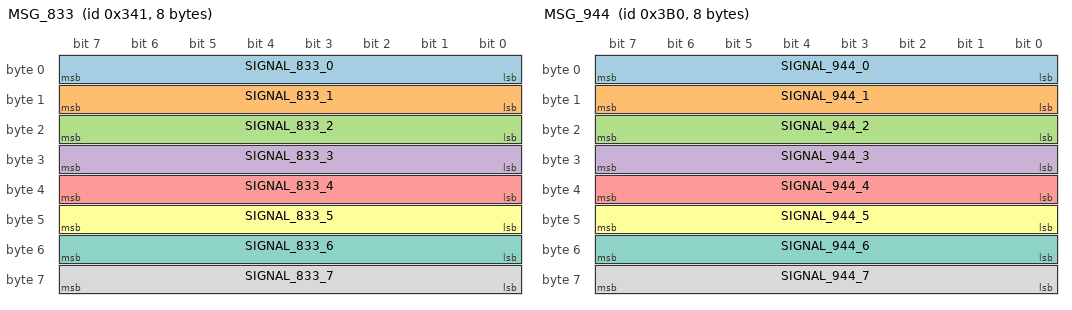
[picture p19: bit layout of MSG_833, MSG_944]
BO_ 833 MSG_833 : 8 VECTOR
    SG_ SIGNAL_833_0 : 0|8@1+ (1,0) [0|255] "" VECTOR
    SG_ SIGNAL_833_1 : 8|8@1+ (1,0) [0|255] "" VECTOR
    SG_ SIGNAL_833_2 : 16|8@1+ (1,0) [0|255] "" VECTOR
    SG_ SIGNAL_833_3 : 24|8@1+ (1,0) [0|255] "" VECTOR
    SG_ SIGNAL_833_4 : 32|8@1+ (1,0) [0|255] "" VECTOR
    SG_ SIGNAL_833_5 : 40|8@1+ (1,0) [0|255] "" VECTOR
    SG_ SIGNAL_833_6 : 48|8@1+ (1,0) [0|255] "" VECTOR
    SG_ SIGNAL_833_7 : 56|8@1+ (1,0) [0|255] "" VECTOR

BO_ 944 MSG_944 : 8 VECTOR
    SG_ SIGNAL_944_0 : 0|8@1+ (1,0) [0|255] "" VECTOR
    SG_ SIGNAL_944_1 : 8|8@1+ (1,0) [0|255] "" VECTOR
    SG_ SIGNAL_944_2 : 16|8@1+ (1,0) [0|255] "" VECTOR
    SG_ SIGNAL_944_3 : 24|8@1+ (1,0) [0|255] "" VECTOR
    SG_ SIGNAL_944_4 : 32|8@1+ (1,0) [0|255] "" VECTOR
    SG_ SIGNAL_944_5 : 40|8@1+ (1,0) [0|255] "" VECTOR
    SG_ SIGNAL_944_6 : 48|8@1+ (1,0) [0|255] "" VECTOR
    SG_ SIGNAL_944_7 : 56|8@1+ (1,0) [0|255] "" VECTOR

BO_ 575 MSG_575 : 8 VECTOR
    SG_ SIGNAL_575_0 : 0|8@1+ (1,0) [0|255] "" VECTOR
    SG_ SIGNAL_575_1 : 8|8@1+ (1,0) [0|255] "" VECTOR
    SG_ SIGNAL_575_2 : 16|8@1+ (1,0) [0|255] "" VECTOR
    SG_ SIGNAL_575_3 : 24|8@1+ (1,0) [0|255] "" VECTOR
    SG_ SIGNAL_575_4 : 32|8@1+ (1,0) [0|255] "" VECTOR
    SG_ SIGNAL_575_5 : 40|8@1+ (1,0) [0|255] "" VECTOR
    SG_ SIGNAL_575_6 : 48|8@1+ (1,0) [0|255] "" VECTOR
    SG_ SIGNAL_575_7 : 56|8@1+ (1,0) [0|255] "" VECTOR

BO_ 985 MSG_985 : 8 VECTOR
    SG_ SIGNAL_985_0 : 0|8@1+ (1,0) [0|255] "" VECTOR
    SG_ SIGNAL_985_1 : 8|8@1+ (1,0) [0|255] "" VECTOR
    SG_ SIGNAL_985_2 : 16|8@1+ (1,0) [0|255] "" VECTOR
    SG_ SIGNAL_985_3 : 24|8@1+ (1,0) [0|255] "" VECTOR
    SG_ SIGNAL_985_4 : 32|8@1+ (1,0) [0|255] "" VECTOR
    SG_ SIGNAL_985_5 : 40|8@1+ (1,0) [0|255] "" VECTOR
    SG_ SIGNAL_985_6 : 48|8@1+ (1,0) [0|255] "" VECTOR
    SG_ SIGNAL_985_7 : 56|8@1+ (1,0) [0|255] "" VECTOR

BO_ 1189 MSG_1189 : 8 VECTOR
    SG_ SIGNAL_1189_0 : 0|8@1+ (1,0) [0|255] "" VECTOR
    SG_ SIGNAL_1189_1 : 8|8@1+ (1,0) [0|255] "" VECTOR
    SG_ SIGNAL_1189_2 : 16|8@1+ (1,0) [0|255] "" VECTOR
    SG_ SIGNAL_1189_3 : 24|8@1+ (1,0) [0|255] "" VECTOR
    SG_ SIGNAL_1189_4 : 32|8@1+ (1,0) [0|255] "" VECTOR
    SG_ SIGNAL_1189_5 : 40|8@1+ (1,0) [0|255] "" VECTOR
    SG_ SIGNAL_1189_6 : 48|8@1+ (1,0) [0|255] "" VECTOR
    SG_ SIGNAL_1189_7 : 56|8@1+ (1,0) [0|255] "" VECTOR

BO_ 450 MSG_450 : 8 VECTOR
    SG_ SIGNAL_450_0 : 0|8@1+ (1,0) [0|255] "" VECTOR
    SG_ SIGNAL_450_1 : 8|8@1+ (1,0) [0|255] "" VECTOR
    SG_ SIGNAL_450_2 : 16|8@1+ (1,0) [0|255] "" VECTOR
    SG_ SIGNAL_450_3 : 24|8@1+ (1,0) [0|255] "" VECTOR
    SG_ SIGNAL_450_4 : 32|8@1+ (1,0) [0|255] "" VECTOR
    SG_ SIGNAL_450_5 : 40|8@1+ (1,0) [0|255] "" VECTOR
    SG_ SIGNAL_450_6 : 48|8@1+ (1,0) [0|255] "" VECTOR
    SG_ SIGNAL_450_7 : 56|8@1+ (1,0) [0|255] "" VECTOR

BO_ 1098 MSG_1098 : 8 VECTOR
    SG_ SIGNAL_1098_0 : 0|8@1+ (1,0) [0|255] "" VECTOR
    SG_ SIGNAL_1098_1 : 8|8@1+ (1,0) [0|255] "" VECTOR
    SG_ SIGNAL_1098_2 : 16|8@1+ (1,0) [0|255] "" VECTOR
    SG_ SIGNAL_1098_3 : 24|8@1+ (1,0) [0|255] "" VECTOR
    SG_ SIGNAL_1098_4 : 32|8@1+ (1,0) [0|255] "" VECTOR
    SG_ SIGNAL_1098_5 : 40|8@1+ (1,0) [0|255] "" VECTOR
    SG_ SIGNAL_1098_6 : 48|8@1+ (1,0) [0|255] "" VECTOR
    SG_ SIGNAL_1098_7 : 56|8@1+ (1,0) [0|255] "" VECTOR

BO_ 537 MSG_537 : 8 VECTOR
    SG_ SIGNAL_537_0 : 0|8@1+ (1,0) [0|255] "" VECTOR
    SG_ SIGNAL_537_1 : 8|8@1+ (1,0) [0|255] "" VECTOR
    SG_ SIGNAL_537_2 : 16|8@1+ (1,0) [0|255] "" VECTOR
    SG_ SIGNAL_537_3 : 24|8@1+ (1,0) [0|255] "" VECTOR
    SG_ SIGNAL_537_4 : 32|8@1+ (1,0) [0|255] "" VECTOR
    SG_ SIGNAL_537_5 : 40|8@1+ (1,0) [0|255] "" VECTOR
    SG_ SIGNAL_537_6 : 48|8@1+ (1,0) [0|255] "" VECTOR
    SG_ SIGNAL_537_7 : 56|8@1+ (1,0) [0|255] "" VECTOR

BO_ 660 MSG_660 : 8 VECTOR
    SG_ SIGNAL_660_0 : 0|8@1+ (1,0) [0|255] "" VECTOR
    SG_ SIGNAL_660_1 : 8|8@1+ (1,0) [0|255] "" VECTOR
    SG_ SIGNAL_660_2 : 16|8@1+ (1,0) [0|255] "" VECTOR
    SG_ SIGNAL_660_3 : 24|8@1+ (1,0) [0|255] "" VECTOR
    SG_ SIGNAL_660_4 : 32|8@1+ (1,0) [0|255] "" VECTOR
    SG_ SIGNAL_660_5 : 40|8@1+ (1,0) [0|255] "" VECTOR
    SG_ SIGNAL_660_6 : 48|8@1+ (1,0) [0|255] "" VECTOR
    SG_ SIGNAL_660_7 : 56|8@1+ (1,0) [0|255] "" VECTOR

BO_ 301 MSG_301 : 8 VECTOR
    SG_ SIGNAL_301_0 : 0|8@1+ (1,0) [0|255] "" VECTOR
    SG_ SIGNAL_301_1 : 8|8@1+ (1,0) [0|255] "" VECTOR
    SG_ SIGNAL_301_2 : 16|8@1+ (1,0) [0|255] "" VECTOR
    SG_ SIGNAL_301_3 : 24|8@1+ (1,0) [0|255] "" VECTOR
    SG_ SIGNAL_301_4 : 32|8@1+ (1,0) [0|255] "" VECTOR
    SG_ SIGNAL_301_5 : 40|8@1+ (1,0) [0|255] "" VECTOR
    SG_ SIGNAL_301_6 : 48|8@1+ (1,0) [0|255] "" VECTOR
    SG_ SIGNAL_301_7 : 56|8@1+ (1,0) [0|255] "" VECTOR

BO_ 803 MSG_803 : 8 VECTOR
    SG_ SIGNAL_803_0 : 0|8@1+ (1,0) [0|255] "" VECTOR
    SG_ SIGNAL_803_1 : 8|8@1+ (1,0) [0|255] "" VECTOR
    SG_ SIGNAL_803_2 : 16|8@1+ (1,0) [0|255] "" VECTOR
    SG_ SIGNAL_803_3 : 24|8@1+ (1,0) [0|255] "" VECTOR
    SG_ SIGNAL_803_4 : 32|8@1+ (1,0) [0|255] "" VECTOR
    SG_ SIGNAL_803_5 : 40|8@1+ (1,0) [0|255] "" VECTOR
    SG_ SIGNAL_803_6 : 48|8@1+ (1,0) [0|255] "" VECTOR
    SG_ SIGNAL_803_7 : 56|8@1+ (1,0) [0|255] "" VECTOR

BO_ 337 MSG_337 : 8 VECTOR
    SG_ SIGNAL_337_0 : 0|8@1+ (1,0) [0|255] "" VECTOR
    SG_ SIGNAL_337_1 : 8|8@1+ (1,0) [0|255] "" VECTOR
    SG_ SIGNAL_337_2 : 16|8@1+ (1,0) [0|255] "" VECTOR
    SG_ SIGNAL_337_3 : 24|8@1+ (1,0) [0|255] "" VECTOR
    SG_ SIGNAL_337_4 : 32|8@1+ (1,0) [0|255] "" VECTOR
    SG_ SIGNAL_337_5 : 40|8@1+ (1,0) [0|255] "" VECTOR
    SG_ SIGNAL_337_6 : 48|8@1+ (1,0) [0|255] "" VECTOR
    SG_ SIGNAL_337_7 : 56|8@1+ (1,0) [0|255] "" VECTOR

BO_ 1097 MSG_1097 : 8 VECTOR
    SG_ SIGNAL_1097_0 : 0|8@1+ (1,0) [0|255] "" VECTOR
    SG_ SIGNAL_1097_1 : 8|8@1+ (1,0) [0|255] "" VECTOR
    SG_ SIGNAL_1097_2 : 16|8@1+ (1,0) [0|255] "" VECTOR
    SG_ SIGNAL_1097_3 : 24|8@1+ (1,0) [0|255] "" VECTOR
    SG_ SIGNAL_1097_4 : 32|8@1+ (1,0) [0|255] "" VECTOR
    SG_ SIGNAL_1097_5 : 40|8@1+ (1,0) [0|255] "" VECTOR
    SG_ SIGNAL_1097_6 : 48|8@1+ (1,0) [0|255] "" VECTOR
    SG_ SIGNAL_1097_7 : 56|8@1+ (1,0) [0|255] "" VECTOR

BO_ 1023 MSG_1023 : 8 VECTOR
    SG_ SIGNAL_1023_0 : 0|8@1+ (1,0) [0|255] "" VECTOR
    SG_ SIGNAL_1023_1 : 8|8@1+ (1,0) [0|255] "" VECTOR
    SG_ SIGNAL_1023_2 : 16|8@1+ (1,0) [0|255] "" VECTOR
    SG_ SIGNAL_1023_3 : 24|8@1+ (1,0) [0|255] "" VECTOR
    SG_ SIGNAL_1023_4 : 32|8@1+ (1,0) [0|255] "" VECTOR
    SG_ SIGNAL_1023_5 : 40|8@1+ (1,0) [0|255] "" VECTOR
    SG_ SIGNAL_1023_6 : 48|8@1+ (1,0) [0|255] "" VECTOR
    SG_ SIGNAL_1023_7 : 56|8@1+ (1,0) [0|255] "" VECTOR

BO_ 786 MSG_786 : 8 VECTOR
    SG_ SIGNAL_786_0 : 0|8@1+ (1,0) [0|255] "" VECTOR
    SG_ SIGNAL_786_1 : 8|8@1+ (1,0) [0|255] "" VECTOR
    SG_ SIGNAL_786_2 : 16|8@1+ (1,0) [0|255] "" VECTOR
    SG_ SIGNAL_786_3 : 24|8@1+ (1,0) [0|255] "" VECTOR
    SG_ SIGNAL_786_4 : 32|8@1+ (1,0) [0|255] "" VECTOR
    SG_ SIGNAL_786_5 : 40|8@1+ (1,0) [0|255] "" VECTOR
    SG_ SIGNAL_786_6 : 48|8@1+ (1,0) [0|255] "" VECTOR
    SG_ SIGNAL_786_7 : 56|8@1+ (1,0) [0|255] "" VECTOR

BO_ 798 MSG_798 : 8 VECTOR
    SG_ SIGNAL_798_0 : 0|8@1+ (1,0) [0|255] "" VECTOR
    SG_ SIGNAL_798_1 : 8|8@1+ (1,0) [0|255] "" VECTOR
    SG_ SIGNAL_798_2 : 16|8@1+ (1,0) [0|255] "" VECTOR
    SG_ SIGNAL_798_3 : 24|8@1+ (1,0) [0|255] "" VECTOR
    SG_ SIGNAL_798_4 : 32|8@1+ (1,0) [0|255] "" VECTOR
    SG_ SIGNAL_798_5 : 40|8@1+ (1,0) [0|255] "" VECTOR
    SG_ SIGNAL_798_6 : 48|8@1+ (1,0) [0|255] "" VECTOR
    SG_ SIGNAL_798_7 : 56|8@1+ (1,0) [0|255] "" VECTOR

BO_ 522 MSG_522 : 8 VECTOR
    SG_ SIGNAL_522_0 : 0|8@1+ (1,0) [0|255] "" VECTOR
    SG_ SIGNAL_522_1 : 8|8@1+ (1,0) [0|255] "" VECTOR
    SG_ SIGNAL_522_2 : 16|8@1+ (1,0) [0|255] "" VECTOR
    SG_ SIGNAL_522_3 : 24|8@1+ (1,0) [0|255] "" VECTOR
    SG_ SIGNAL_522_4 : 32|8@1+ (1,0) [0|255] "" VECTOR
    SG_ SIGNAL_522_5 : 40|8@1+ (1,0) [0|255] "" VECTOR
    SG_ SIGNAL_522_6 : 48|8@1+ (1,0) [0|255] "" VECTOR
    SG_ SIGNAL_522_7 : 56|8@1+ (1,0) [0|255] "" VECTOR

BO_ 576 MSG_576 : 8 VECTOR
    SG_ SIGNAL_576_0 : 0|8@1+ (1,0) [0|255] "" VECTOR
    SG_ SIGNAL_576_1 : 8|8@1+ (1,0) [0|255] "" VECTOR
    SG_ SIGNAL_576_2 : 16|8@1+ (1,0) [0|255] "" VECTOR
    SG_ SIGNAL_576_3 : 24|8@1+ (1,0) [0|255] "" VECTOR
    SG_ SIGNAL_576_4 : 32|8@1+ (1,0) [0|255] "" VECTOR
    SG_ SIGNAL_576_5 : 40|8@1+ (1,0) [0|255] "" VECTOR
    SG_ SIGNAL_576_6 : 48|8@1+ (1,0) [0|255] "" VECTOR
    SG_ SIGNAL_576_7 : 56|8@1+ (1,0) [0|255] "" VECTOR

BO_ 835 MSG_835 : 8 VECTOR
    SG_ SIGNAL_835_0 : 0|8@1+ (1,0) [0|255] "" VECTOR
    SG_ SIGNAL_835_1 : 8|8@1+ (1,0) [0|255] "" VECTOR
    SG_ SIGNAL_835_2 : 16|8@1+ (1,0) [0|255] "" VECTOR
    SG_ SIGNAL_835_3 : 24|8@1+ (1,0) [0|255] "" VECTOR
    SG_ SIGNAL_835_4 : 32|8@1+ (1,0) [0|255] "" VECTOR
    SG_ SIGNAL_835_5 : 40|8@1+ (1,0) [0|255] "" VECTOR
    SG_ SIGNAL_835_6 : 48|8@1+ (1,0) [0|255] "" VECTOR
    SG_ SIGNAL_835_7 : 56|8@1+ (1,0) [0|255] "" VECTOR

BO_ 748 MSG_748 : 8 VECTOR
    SG_ SIGNAL_748_0 : 0|8@1+ (1,0) [0|255] "" VECTOR
    SG_ SIGNAL_748_1 : 8|8@1+ (1,0) [0|255] "" VECTOR
    SG_ SIGNAL_748_2 : 16|8@1+ (1,0) [0|255] "" VECTOR
    SG_ SIGNAL_748_3 : 24|8@1+ (1,0) [0|255] "" VECTOR
    SG_ SIGNAL_748_4 : 32|8@1+ (1,0) [0|255] "" VECTOR
    SG_ SIGNAL_748_5 : 40|8@1+ (1,0) [0|255] "" VECTOR
    SG_ SIGNAL_748_6 : 48|8@1+ (1,0) [0|255] "" VECTOR
    SG_ SIGNAL_748_7 : 56|8@1+ (1,0) [0|255] "" VECTOR

BO_ 1163 MSG_1163 : 8 VECTOR
    SG_ SIGNAL_1163_0 : 0|8@1+ (1,0) [0|255] "" VECTOR
    SG_ SIGNAL_1163_1 : 8|8@1+ (1,0) [0|255] "" VECTOR
    SG_ SIGNAL_1163_2 : 16|8@1+ (1,0) [0|255] "" VECTOR
    SG_ SIGNAL_1163_3 : 24|8@1+ (1,0) [0|255] "" VECTOR
    SG_ SIGNAL_1163_4 : 32|8@1+ (1,0) [0|255] "" VECTOR
    SG_ SIGNAL_1163_5 : 40|8@1+ (1,0) [0|255] "" VECTOR
    SG_ SIGNAL_1163_6 : 48|8@1+ (1,0) [0|255] "" VECTOR
    SG_ SIGNAL_1163_7 : 56|8@1+ (1,0) [0|255] "" VECTOR

BO_ 878 MSG_878 : 8 VECTOR
    SG_ SIGNAL_878_0 : 0|8@1+ (1,0) [0|255] "" VECTOR
    SG_ SIGNAL_878_1 : 8|8@1+ (1,0) [0|255] "" VECTOR
    SG_ SIGNAL_878_2 : 16|8@1+ (1,0) [0|255] "" VECTOR
    SG_ SIGNAL_878_3 : 24|8@1+ (1,0) [0|255] "" VECTOR
    SG_ SIGNAL_878_4 : 32|8@1+ (1,0) [0|255] "" VECTOR
    SG_ SIGNAL_878_5 : 40|8@1+ (1,0) [0|255] "" VECTOR
    SG_ SIGNAL_878_6 : 48|8@1+ (1,0) [0|255] "" VECTOR
    SG_ SIGNAL_878_7 : 56|8@1+ (1,0) [0|255] "" VECTOR

BO_ 1052 MSG_1052 : 8 VECTOR
    SG_ SIGNAL_1052_0 : 0|8@1+ (1,0) [0|255] "" VECTOR
    SG_ SIGNAL_1052_1 : 8|8@1+ (1,0) [0|255] "" VECTOR
    SG_ SIGNAL_1052_2 : 16|8@1+ (1,0) [0|255] "" VECTOR
    SG_ SIGNAL_1052_3 : 24|8@1+ (1,0) [0|255] "" VECTOR
    SG_ SIGNAL_1052_4 : 32|8@1+ (1,0) [0|255] "" VECTOR
    SG_ SIGNAL_1052_5 : 40|8@1+ (1,0) [0|255] "" VECTOR
    SG_ SIGNAL_1052_6 : 48|8@1+ (1,0) [0|255] "" VECTOR
    SG_ SIGNAL_1052_7 : 56|8@1+ (1,0) [0|255] "" VECTOR

BO_ 1169 MSG_1169 : 8 VECTOR
    SG_ SIGNAL_1169_0 : 0|8@1+ (1,0) [0|255] "" VECTOR
    SG_ SIGNAL_1169_1 : 8|8@1+ (1,0) [0|255] "" VECTOR
    SG_ SIGNAL_1169_2 : 16|8@1+ (1,0) [0|255] "" VECTOR
    SG_ SIGNAL_1169_3 : 24|8@1+ (1,0) [0|255] "" VECTOR
    SG_ SIGNAL_1169_4 : 32|8@1+ (1,0) [0|255] "" VECTOR
    SG_ SIGNAL_1169_5 : 40|8@1+ (1,0) [0|255] "" VECTOR
    SG_ SIGNAL_1169_6 : 48|8@1+ (1,0) [0|255] "" VECTOR
    SG_ SIGNAL_1169_7 : 56|8@1+ (1,0) [0|255] "" VECTOR

BO_ 1297 MSG_1297 : 8 VECTOR
    SG_ SIGNAL_1297_0 : 0|8@1+ (1,0) [0|255] "" VECTOR
    SG_ SIGNAL_1297_1 : 8|8@1+ (1,0) [0|255] "" VECTOR
    SG_ SIGNAL_1297_2 : 16|8@1+ (1,0) [0|255] "" VECTOR
    SG_ SIGNAL_1297_3 : 24|8@1+ (1,0) [0|255] "" VECTOR
    SG_ SIGNAL_1297_4 : 32|8@1+ (1,0) [0|255] "" VECTOR
    SG_ SIGNAL_1297_5 : 40|8@1+ (1,0) [0|255] "" VECTOR
    SG_ SIGNAL_1297_6 : 48|8@1+ (1,0) [0|255] "" VECTOR
    SG_ SIGNAL_1297_7 : 56|8@1+ (1,0) [0|255] "" VECTOR

BO_ 973 MSG_973 : 8 VECTOR
    SG_ SIGNAL_973_0 : 0|8@1+ (1,0) [0|255] "" VECTOR
    SG_ SIGNAL_973_1 : 8|8@1+ (1,0) [0|255] "" VECTOR
    SG_ SIGNAL_973_2 : 16|8@1+ (1,0) [0|255] "" VECTOR
    SG_ SIGNAL_973_3 : 24|8@1+ (1,0) [0|255] "" VECTOR
    SG_ SIGNAL_973_4 : 32|8@1+ (1,0) [0|255] "" VECTOR
    SG_ SIGNAL_973_5 : 40|8@1+ (1,0) [0|255] "" VECTOR
    SG_ SIGNAL_973_6 : 48|8@1+ (1,0) [0|255] "" VECTOR
    SG_ SIGNAL_973_7 : 56|8@1+ (1,0) [0|255] "" VECTOR

BO_ 1298 MSG_1298 : 8 VECTOR
    SG_ SIGNAL_1298_0 : 0|8@1+ (1,0) [0|255] "" VECTOR
    SG_ SIGNAL_1298_1 : 8|8@1+ (1,0) [0|255] "" VECTOR
    SG_ SIGNAL_1298_2 : 16|8@1+ (1,0) [0|255] "" VECTOR
    SG_ SIGNAL_1298_3 : 24|8@1+ (1,0) [0|255] "" VECTOR
    SG_ SIGNAL_1298_4 : 32|8@1+ (1,0) [0|255] "" VECTOR
    SG_ SIGNAL_1298_5 : 40|8@1+ (1,0) [0|255] "" VECTOR
    SG_ SIGNAL_1298_6 : 48|8@1+ (1,0) [0|255] "" VECTOR
    SG_ SIGNAL_1298_7 : 56|8@1+ (1,0) [0|255] "" VECTOR

BO_ 1031 MSG_1031 : 8 VECTOR
    SG_ SIGNAL_1031_0 : 0|8@1+ (1,0) [0|255] "" VECTOR
    SG_ SIGNAL_1031_1 : 8|8@1+ (1,0) [0|255] "" VECTOR
    SG_ SIGNAL_1031_2 : 16|8@1+ (1,0) [0|255] "" VECTOR
    SG_ SIGNAL_1031_3 : 24|8@1+ (1,0) [0|255] "" VECTOR
    SG_ SIGNAL_1031_4 : 32|8@1+ (1,0) [0|255] "" VECTOR
    SG_ SIGNAL_1031_5 : 40|8@1+ (1,0) [0|255] "" VECTOR
    SG_ SIGNAL_1031_6 : 48|8@1+ (1,0) [0|255] "" VECTOR
    SG_ SIGNAL_1031_7 : 56|8@1+ (1,0) [0|255] "" VECTOR

BO_ 1076 MSG_1076 : 8 VECTOR
    SG_ SIGNAL_1076_0 : 0|8@1+ (1,0) [0|255] "" VECTOR
    SG_ SIGNAL_1076_1 : 8|8@1+ (1,0) [0|255] "" VECTOR
    SG_ SIGNAL_1076_2 : 16|8@1+ (1,0) [0|255] "" VECTOR
    SG_ SIGNAL_1076_3 : 24|8@1+ (1,0) [0|255] "" VECTOR
    SG_ SIGNAL_1076_4 : 32|8@1+ (1,0) [0|255] "" VECTOR
    SG_ SIGNAL_1076_5 : 40|8@1+ (1,0) [0|255] "" VECTOR
    SG_ SIGNAL_1076_6 : 48|8@1+ (1,0) [0|255] "" VECTOR
    SG_ SIGNAL_1076_7 : 56|8@1+ (1,0) [0|255] "" VECTOR

BO_ 1037 MSG_1037 : 8 VECTOR
    SG_ SIGNAL_1037_0 : 0|8@1+ (1,0) [0|255] "" VECTOR
    SG_ SIGNAL_1037_1 : 8|8@1+ (1,0) [0|255] "" VECTOR
    SG_ SIGNAL_1037_2 : 16|8@1+ (1,0) [0|255] "" VECTOR
    SG_ SIGNAL_1037_3 : 24|8@1+ (1,0) [0|255] "" VECTOR
    SG_ SIGNAL_1037_4 : 32|8@1+ (1,0) [0|255] "" VECTOR
    SG_ SIGNAL_1037_5 : 40|8@1+ (1,0) [0|255] "" VECTOR
    SG_ SIGNAL_1037_6 : 48|8@1+ (1,0) [0|255] "" VECTOR
    SG_ SIGNAL_1037_7 : 56|8@1+ (1,0) [0|255] "" VECTOR

BO_ 1038 MSG_1038 : 8 VECTOR
    SG_ SIGNAL_1038_0 : 0|8@1+ (1,0) [0|255] "" VECTOR
    SG_ SIGNAL_1038_1 : 8|8@1+ (1,0) [0|255] "" VECTOR
    SG_ SIGNAL_1038_2 : 16|8@1+ (1,0) [0|255] "" VECTOR
    SG_ SIGNAL_1038_3 : 24|8@1+ (1,0) [0|255] "" VECTOR
    SG_ SIGNAL_1038_4 : 32|8@1+ (1,0) [0|255] "" VECTOR
    SG_ SIGNAL_1038_5 : 40|8@1+ (1,0) [0|255] "" VECTOR
    SG_ SIGNAL_1038_6 : 48|8@1+ (1,0) [0|255] "" VECTOR
    SG_ SIGNAL_1038_7 : 56|8@1+ (1,0) [0|255] "" VECTOR

BO_ 588 MSG_588 : 8 VECTOR
    SG_ SIGNAL_588_0 : 0|8@1+ (1,0) [0|255] "" VECTOR
    SG_ SIGNAL_588_1 : 8|8@1+ (1,0) [0|255] "" VECTOR
    SG_ SIGNAL_588_2 : 16|8@1+ (1,0) [0|255] "" VECTOR
    SG_ SIGNAL_588_3 : 24|8@1+ (1,0) [0|255] "" VECTOR
    SG_ SIGNAL_588_4 : 32|8@1+ (1,0) [0|255] "" VECTOR
    SG_ SIGNAL_588_5 : 40|8@1+ (1,0) [0|255] "" VECTOR
    SG_ SIGNAL_588_6 : 48|8@1+ (1,0) [0|255] "" VECTOR
    SG_ SIGNAL_588_7 : 56|8@1+ (1,0) [0|255] "" VECTOR

BO_ 694 MSG_694 : 8 VECTOR
    SG_ SIGNAL_694_0 : 0|8@1+ (1,0) [0|255] "" VECTOR
    SG_ SIGNAL_694_1 : 8|8@1+ (1,0) [0|255] "" VECTOR
    SG_ SIGNAL_694_2 : 16|8@1+ (1,0) [0|255] "" VECTOR
    SG_ SIGNAL_694_3 : 24|8@1+ (1,0) [0|255] "" VECTOR
    SG_ SIGNAL_694_4 : 32|8@1+ (1,0) [0|255] "" VECTOR
    SG_ SIGNAL_694_5 : 40|8@1+ (1,0) [0|255] "" VECTOR
    SG_ SIGNAL_694_6 : 48|8@1+ (1,0) [0|255] "" VECTOR
    SG_ SIGNAL_694_7 : 56|8@1+ (1,0) [0|255] "" VECTOR

BO_ 1274 MSG_1274 : 8 VECTOR
    SG_ SIGNAL_1274_0 : 0|8@1+ (1,0) [0|255] "" VECTOR
    SG_ SIGNAL_1274_1 : 8|8@1+ (1,0) [0|255] "" VECTOR
    SG_ SIGNAL_1274_2 : 16|8@1+ (1,0) [0|255] "" VECTOR
    SG_ SIGNAL_1274_3 : 24|8@1+ (1,0) [0|255] "" VECTOR
    SG_ SIGNAL_1274_4 : 32|8@1+ (1,0) [0|255] "" VECTOR
    SG_ SIGNAL_1274_5 : 40|8@1+ (1,0) [0|255] "" VECTOR
    SG_ SIGNAL_1274_6 : 48|8@1+ (1,0) [0|255] "" VECTOR
    SG_ SIGNAL_1274_7 : 56|8@1+ (1,0) [0|255] "" VECTOR

BO_ 140 MSG_140 : 8 VECTOR
    SG_ SIGNAL_140_0 : 0|8@1+ (1,0) [0|255] "" VECTOR
    SG_ SIGNAL_140_1 : 8|8@1+ (1,0) [0|255] "" VECTOR
    SG_ SIGNAL_140_2 : 16|8@1+ (1,0) [0|255] "" VECTOR
    SG_ SIGNAL_140_3 : 24|8@1+ (1,0) [0|255] "" VECTOR
    SG_ SIGNAL_140_4 : 32|8@1+ (1,0) [0|255] "" VECTOR
    SG_ SIGNAL_140_5 : 40|8@1+ (1,0) [0|255] "" VECTOR
    SG_ SIGNAL_140_6 : 48|8@1+ (1,0) [0|255] "" VECTOR
    SG_ SIGNAL_140_7 : 56|8@1+ (1,0) [0|255] "" VECTOR

BO_ 1178 MSG_1178 : 8 VECTOR
    SG_ SIGNAL_1178_0 : 0|8@1+ (1,0) [0|255] "" VECTOR
    SG_ SIGNAL_1178_1 : 8|8@1+ (1,0) [0|255] "" VECTOR
    SG_ SIGNAL_1178_2 : 16|8@1+ (1,0) [0|255] "" VECTOR
    SG_ SIGNAL_1178_3 : 24|8@1+ (1,0) [0|255] "" VECTOR
    SG_ SIGNAL_1178_4 : 32|8@1+ (1,0) [0|255] "" VECTOR
    SG_ SIGNAL_1178_5 : 40|8@1+ (1,0) [0|255] "" VECTOR
    SG_ SIGNAL_1178_6 : 48|8@1+ (1,0) [0|255] "" VECTOR
    SG_ SIGNAL_1178_7 : 56|8@1+ (1,0) [0|255] "" VECTOR

BO_ 1215 MSG_1215 : 8 VECTOR
    SG_ SIGNAL_1215_0 : 0|8@1+ (1,0) [0|255] "" VECTOR
    SG_ SIGNAL_1215_1 : 8|8@1+ (1,0) [0|255] "" VECTOR
    SG_ SIGNAL_1215_2 : 16|8@1+ (1,0) [0|255] "" VECTOR
    SG_ SIGNAL_1215_3 : 24|8@1+ (1,0) [0|255] "" VECTOR
    SG_ SIGNAL_1215_4 : 32|8@1+ (1,0) [0|255] "" VECTOR
    SG_ SIGNAL_1215_5 : 40|8@1+ (1,0) [0|255] "" VECTOR
    SG_ SIGNAL_1215_6 : 48|8@1+ (1,0) [0|255] "" VECTOR
    SG_ SIGNAL_1215_7 : 56|8@1+ (1,0) [0|255] "" VECTOR

BO_ 1278 MSG_1278 : 8 VECTOR
    SG_ SIGNAL_1278_0 : 0|8@1+ (1,0) [0|255] "" VECTOR
    SG_ SIGNAL_1278_1 : 8|8@1+ (1,0) [0|255] "" VECTOR
    SG_ SIGNAL_1278_2 : 16|8@1+ (1,0) [0|255] "" VECTOR
    SG_ SIGNAL_1278_3 : 24|8@1+ (1,0) [0|255] "" VECTOR
    SG_ SIGNAL_1278_4 : 32|8@1+ (1,0) [0|255] "" VECTOR
    SG_ SIGNAL_1278_5 : 40|8@1+ (1,0) [0|255] "" VECTOR
    SG_ SIGNAL_1278_6 : 48|8@1+ (1,0) [0|255] "" VECTOR
    SG_ SIGNAL_1278_7 : 56|8@1+ (1,0) [0|255] "" VECTOR

BO_ 847 MSG_847 : 8 VECTOR
    SG_ SIGNAL_847_0 : 0|8@1+ (1,0) [0|255] "" VECTOR
    SG_ SIGNAL_847_1 : 8|8@1+ (1,0) [0|255] "" VECTOR
    SG_ SIGNAL_847_2 : 16|8@1+ (1,0) [0|255] "" VECTOR
    SG_ SIGNAL_847_3 : 24|8@1+ (1,0) [0|255] "" VECTOR
    SG_ SIGNAL_847_4 : 32|8@1+ (1,0) [0|255] "" VECTOR
    SG_ SIGNAL_847_5 : 40|8@1+ (1,0) [0|255] "" VECTOR
    SG_ SIGNAL_847_6 : 48|8@1+ (1,0) [0|255] "" VECTOR
    SG_ SIGNAL_847_7 : 56|8@1+ (1,0) [0|255] "" VECTOR

BO_ 1193 MSG_1193 : 8 VECTOR
    SG_ SIGNAL_1193_0 : 0|8@1+ (1,0) [0|255] "" VECTOR
    SG_ SIGNAL_1193_1 : 8|8@1+ (1,0) [0|255] "" VECTOR
    SG_ SIGNAL_1193_2 : 16|8@1+ (1,0) [0|255] "" VECTOR
    SG_ SIGNAL_1193_3 : 24|8@1+ (1,0) [0|255] "" VECTOR
    SG_ SIGNAL_1193_4 : 32|8@1+ (1,0) [0|255] "" VECTOR
    SG_ SIGNAL_1193_5 : 40|8@1+ (1,0) [0|255] "" VECTOR
    SG_ SIGNAL_1193_6 : 48|8@1+ (1,0) [0|255] "" VECTOR
    SG_ SIGNAL_1193_7 : 56|8@1+ (1,0) [0|255] "" VECTOR

BO_ 797 MSG_797 : 8 VECTOR
    SG_ SIGNAL_797_0 : 0|8@1+ (1,0) [0|255] "" VECTOR
    SG_ SIGNAL_797_1 : 8|8@1+ (1,0) [0|255] "" VECTOR
    SG_ SIGNAL_797_2 : 16|8@1+ (1,0) [0|255] "" VECTOR
    SG_ SIGNAL_797_3 : 24|8@1+ (1,0) [0|255] "" VECTOR
    SG_ SIGNAL_797_4 : 32|8@1+ (1,0) [0|255] "" VECTOR
    SG_ SIGNAL_797_5 : 40|8@1+ (1,0) [0|255] "" VECTOR
    SG_ SIGNAL_797_6 : 48|8@1+ (1,0) [0|255] "" VECTOR
    SG_ SIGNAL_797_7 : 56|8@1+ (1,0) [0|255] "" VECTOR

BO_ 1246 MSG_1246 : 8 VECTOR
    SG_ SIGNAL_1246_0 : 0|8@1+ (1,0) [0|255] "" VECTOR
    SG_ SIGNAL_1246_1 : 8|8@1+ (1,0) [0|255] "" VECTOR
    SG_ SIGNAL_1246_2 : 16|8@1+ (1,0) [0|255] "" VECTOR
    SG_ SIGNAL_1246_3 : 24|8@1+ (1,0) [0|255] "" VECTOR
    SG_ SIGNAL_1246_4 : 32|8@1+ (1,0) [0|255] "" VECTOR
    SG_ SIGNAL_1246_5 : 40|8@1+ (1,0) [0|255] "" VECTOR
    SG_ SIGNAL_1246_6 : 48|8@1+ (1,0) [0|255] "" VECTOR
    SG_ SIGNAL_1246_7 : 56|8@1+ (1,0) [0|255] "" VECTOR

BO_ 1004 MSG_1004 : 8 VECTOR
    SG_ SIGNAL_1004_0 : 0|8@1+ (1,0) [0|255] "" VECTOR
    SG_ SIGNAL_1004_1 : 8|8@1+ (1,0) [0|255] "" VECTOR
    SG_ SIGNAL_1004_2 : 16|8@1+ (1,0) [0|255] "" VECTOR
    SG_ SIGNAL_1004_3 : 24|8@1+ (1,0) [0|255] "" VECTOR
    SG_ SIGNAL_1004_4 : 32|8@1+ (1,0) [0|255] "" VECTOR
    SG_ SIGNAL_1004_5 : 40|8@1+ (1,0) [0|255] "" VECTOR
    SG_ SIGNAL_1004_6 : 48|8@1+ (1,0) [0|255] "" VECTOR
    SG_ SIGNAL_1004_7 : 56|8@1+ (1,0) [0|255] "" VECTOR

BO_ 951 MSG_951 : 8 VECTOR
    SG_ SIGNAL_951_0 : 0|8@1+ (1,0) [0|255] "" VECTOR
    SG_ SIGNAL_951_1 : 8|8@1+ (1,0) [0|255] "" VECTOR
    SG_ SIGNAL_951_2 : 16|8@1+ (1,0) [0|255] "" VECTOR
    SG_ SIGNAL_951_3 : 24|8@1+ (1,0) [0|255] "" VECTOR
    SG_ SIGNAL_951_4 : 32|8@1+ (1,0) [0|255] "" VECTOR
    SG_ SIGNAL_951_5 : 40|8@1+ (1,0) [0|255] "" VECTOR
    SG_ SIGNAL_951_6 : 48|8@1+ (1,0) [0|255] "" VECTOR
    SG_ SIGNAL_951_7 : 56|8@1+ (1,0) [0|255] "" VECTOR

BO_ 724 MSG_724 : 8 VECTOR
    SG_ SIGNAL_724_0 : 0|8@1+ (1,0) [0|255] "" VECTOR
    SG_ SIGNAL_724_1 : 8|8@1+ (1,0) [0|255] "" VECTOR
    SG_ SIGNAL_724_2 : 16|8@1+ (1,0) [0|255] "" VECTOR
    SG_ SIGNAL_724_3 : 24|8@1+ (1,0) [0|255] "" VECTOR
    SG_ SIGNAL_724_4 : 32|8@1+ (1,0) [0|255] "" VECTOR
    SG_ SIGNAL_724_5 : 40|8@1+ (1,0) [0|255] "" VECTOR
    SG_ SIGNAL_724_6 : 48|8@1+ (1,0) [0|255] "" VECTOR
    SG_ SIGNAL_724_7 : 56|8@1+ (1,0) [0|255] "" VECTOR

BO_ 965 MSG_965 : 8 VECTOR
    SG_ SIGNAL_965_0 : 0|8@1+ (1,0) [0|255] "" VECTOR
    SG_ SIGNAL_965_1 : 8|8@1+ (1,0) [0|255] "" VECTOR
    SG_ SIGNAL_965_2 : 16|8@1+ (1,0) [0|255] "" VECTOR
    SG_ SIGNAL_965_3 : 24|8@1+ (1,0) [0|255] "" VECTOR
    SG_ SIGNAL_965_4 : 32|8@1+ (1,0) [0|255] "" VECTOR
    SG_ SIGNAL_965_5 : 40|8@1+ (1,0) [0|255] "" VECTOR
    SG_ SIGNAL_965_6 : 48|8@1+ (1,0) [0|255] "" VECTOR
    SG_ SIGNAL_965_7 : 56|8@1+ (1,0) [0|255] "" VECTOR

BO_ 1141 MSG_1141 : 8 VECTOR
    SG_ SIGNAL_1141_0 : 0|8@1+ (1,0) [0|255] "" VECTOR
    SG_ SIGNAL_1141_1 : 8|8@1+ (1,0) [0|255] "" VECTOR
    SG_ SIGNAL_1141_2 : 16|8@1+ (1,0) [0|255] "" VECTOR
    SG_ SIGNAL_1141_3 : 24|8@1+ (1,0) [0|255] "" VECTOR
    SG_ SIGNAL_1141_4 : 32|8@1+ (1,0) [0|255] "" VECTOR
    SG_ SIGNAL_1141_5 : 40|8@1+ (1,0) [0|255] "" VECTOR
    SG_ SIGNAL_1141_6 : 48|8@1+ (1,0) [0|255] "" VECTOR
    SG_ SIGNAL_1141_7 : 56|8@1+ (1,0) [0|255] "" VECTOR

BO_ 1028 MSG_1028 : 8 VECTOR
    SG_ SIGNAL_1028_0 : 0|8@1+ (1,0) [0|255] "" VECTOR
    SG_ SIGNAL_1028_1 : 8|8@1+ (1,0) [0|255] "" VECTOR
    SG_ SIGNAL_1028_2 : 16|8@1+ (1,0) [0|255] "" VECTOR
    SG_ SIGNAL_1028_3 : 24|8@1+ (1,0) [0|255] "" VECTOR
    SG_ SIGNAL_1028_4 : 32|8@1+ (1,0) [0|255] "" VECTOR
    SG_ SIGNAL_1028_5 : 40|8@1+ (1,0) [0|255] "" VECTOR
    SG_ SIGNAL_1028_6 : 48|8@1+ (1,0) [0|255] "" VECTOR
    SG_ SIGNAL_1028_7 : 56|8@1+ (1,0) [0|255] "" VECTOR

BO_ 1273 MSG_1273 : 8 VECTOR
    SG_ SIGNAL_1273_0 : 0|8@1+ (1,0) [0|255] "" VECTOR
    SG_ SIGNAL_1273_1 : 8|8@1+ (1,0) [0|255] "" VECTOR
    SG_ SIGNAL_1273_2 : 16|8@1+ (1,0) [0|255] "" VECTOR
    SG_ SIGNAL_1273_3 : 24|8@1+ (1,0) [0|255] "" VECTOR
    SG_ SIGNAL_1273_4 : 32|8@1+ (1,0) [0|255] "" VECTOR
    SG_ SIGNAL_1273_5 : 40|8@1+ (1,0) [0|255] "" VECTOR
    SG_ SIGNAL_1273_6 : 48|8@1+ (1,0) [0|255] "" VECTOR
    SG_ SIGNAL_1273_7 : 56|8@1+ (1,0) [0|255] "" VECTOR

BO_ 906 MSG_906 : 8 VECTOR
    SG_ SIGNAL_906_0 : 0|8@1+ (1,0) [0|255] "" VECTOR
    SG_ SIGNAL_906_1 : 8|8@1+ (1,0) [0|255] "" VECTOR
    SG_ SIGNAL_906_2 : 16|8@1+ (1,0) [0|255] "" VECTOR
    SG_ SIGNAL_906_3 : 24|8@1+ (1,0) [0|255] "" VECTOR
    SG_ SIGNAL_906_4 : 32|8@1+ (1,0) [0|255] "" VECTOR
    SG_ SIGNAL_906_5 : 40|8@1+ (1,0) [0|255] "" VECTOR
    SG_ SIGNAL_906_6 : 48|8@1+ (1,0) [0|255] "" VECTOR
    SG_ SIGNAL_906_7 : 56|8@1+ (1,0) [0|255] "" VECTOR
